# ioat91sam7x256 register map
Registers from a debugger description file.
Registers are 32-bit, access not given, no defined reset value unless marked. A register's access mark holds for its fields unless they carry their own. Addresses are absolute; registers are grouped by the start of their names; lines under a group give offsets from that group; [hi:lo] are bit positions; {n}, {i} and the like mark numbered series; 'fields as' and 'values as' point back to an identical list; <NAME> marks a mode.

## AIC
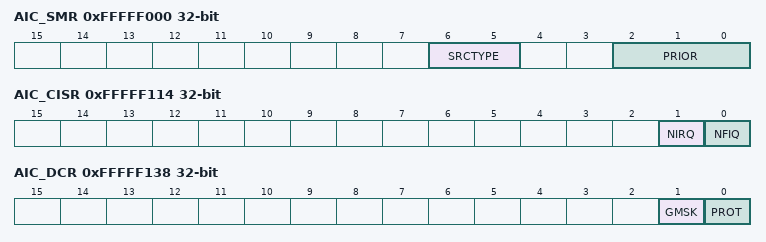
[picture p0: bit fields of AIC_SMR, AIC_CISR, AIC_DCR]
0xFFFFF000 AIC_SMR
  [6:5] SRCTYPE, [2:0] PRIOR
0xFFFFF080 AIC_SVR
0xFFFFF100 AIC_IVR
0xFFFFF104 AIC_FVR
0xFFFFF108 AIC_ISR
0xFFFFF10C AIC_IPR
0xFFFFF110 AIC_IMR
0xFFFFF114 AIC_CISR
  [1] NIRQ, [0] NFIQ
0xFFFFF120 AIC_IECR
0xFFFFF124 AIC_IDCR
0xFFFFF128 AIC_ICCR
0xFFFFF12C AIC_ISCR
0xFFFFF130 AIC_EOICR
0xFFFFF134 AIC_SPU
0xFFFFF138 AIC_DCR
  [1] GMSK, [0] PROT
0xFFFFF140 AIC_FFER
0xFFFFF144 AIC_FFDR
0xFFFFF148 AIC_FFSR

## DBGU
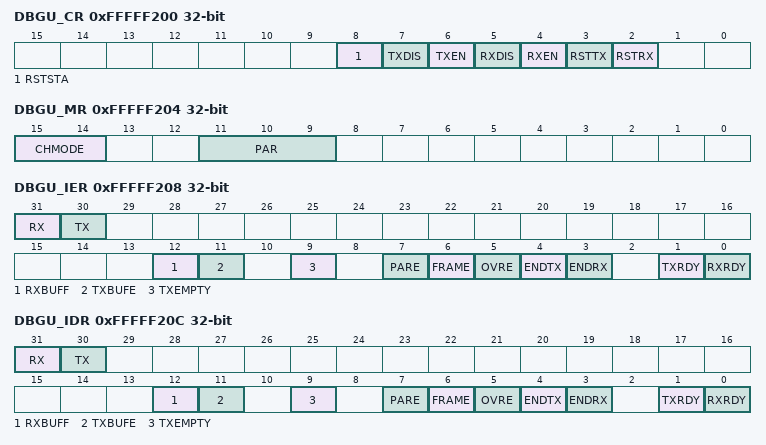
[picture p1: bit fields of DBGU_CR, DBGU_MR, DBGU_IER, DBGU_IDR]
0xFFFFF200 DBGU_CR
  [8] RSTSTA, [7] TXDIS, [6] TXEN, [5] RXDIS, [4] RXEN, [3] RSTTX, [2] RSTRX
0xFFFFF204 DBGU_MR
  [15:14] CHMODE, [11:9] PAR
0xFFFFF208 DBGU_IER
  [31] RX, [30] TX, [12] RXBUFF, [11] TXBUFE, [9] TXEMPTY, [7] PARE, [6] FRAME, [5] OVRE, [4] ENDTX, [3] ENDRX, [1] TXRDY, [0] RXRDY
0xFFFFF20C DBGU_IDR
  fields as DBGU_IER
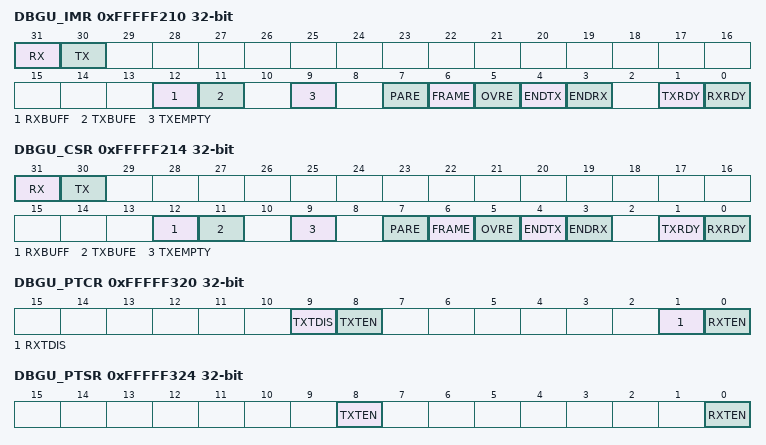
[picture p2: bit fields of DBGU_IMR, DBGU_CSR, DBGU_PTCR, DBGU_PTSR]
0xFFFFF210 DBGU_IMR
  fields as DBGU_IER
0xFFFFF214 DBGU_CSR
  fields as DBGU_IER
0xFFFFF218 DBGU_RHR
0xFFFFF21C DBGU_THR
0xFFFFF220 DBGU_BRGR
0xFFFFF240 DBGU_CIDR
0xFFFFF244 DBGU_EXID
0xFFFFF248 DBGU_FNTR
  [0] NTRST
0xFFFFF300 DBGU_RPR
0xFFFFF304 DBGU_RCR
0xFFFFF308 DBGU_TPR
0xFFFFF30C DBGU_TCR
0xFFFFF310 DBGU_RNPR
0xFFFFF314 DBGU_RNCR
0xFFFFF318 DBGU_TNPR
0xFFFFF31C DBGU_TNCR
0xFFFFF320 DBGU_PTCR
  [9] TXTDIS, [8] TXTEN, [1] RXTDIS, [0] RXTEN
0xFFFFF324 DBGU_PTSR
  [8] TXTEN, [0] RXTEN

## PIOA
0xFFFFF400 PIOA_PER
0xFFFFF404 PIOA_PDR
0xFFFFF408 PIOA_PSR
0xFFFFF410 PIOA_OER
0xFFFFF414 PIOA_ODR
0xFFFFF418 PIOA_OSR
0xFFFFF420 PIOA_IFER
0xFFFFF424 PIOA_IFDR
0xFFFFF428 PIOA_IFSR
0xFFFFF430 PIOA_SODR
0xFFFFF434 PIOA_CODR
0xFFFFF438 PIOA_ODSR
0xFFFFF43C PIOA_PDSR
0xFFFFF440 PIOA_IER
0xFFFFF444 PIOA_IDR
0xFFFFF448 PIOA_IMR
0xFFFFF44C PIOA_ISR
0xFFFFF450 PIOA_MDER
0xFFFFF454 PIOA_MDDR
0xFFFFF458 PIOA_MDSR
0xFFFFF460 PIOA_PPUDR
0xFFFFF464 PIOA_PPUER
0xFFFFF468 PIOA_PPUSR
0xFFFFF470 PIOA_ASR
0xFFFFF474 PIOA_BSR
0xFFFFF478 PIOA_ABSR
0xFFFFF4A0 PIOA_OWER
0xFFFFF4A4 PIOA_OWDR
0xFFFFF4A8 PIOA_OWSR

## PIOB
0xFFFFF600 PIOB_PER
0xFFFFF604 PIOB_PDR
0xFFFFF608 PIOB_PSR
0xFFFFF610 PIOB_OER
0xFFFFF614 PIOB_ODR
0xFFFFF618 PIOB_OSR
0xFFFFF620 PIOB_IFER
0xFFFFF624 PIOB_IFDR
0xFFFFF628 PIOB_IFSR
0xFFFFF630 PIOB_SODR
0xFFFFF634 PIOB_CODR
0xFFFFF638 PIOB_ODSR
0xFFFFF63C PIOB_PDSR
0xFFFFF640 PIOB_IER
0xFFFFF644 PIOB_IDR
0xFFFFF648 PIOB_IMR
0xFFFFF64C PIOB_ISR
0xFFFFF650 PIOB_MDER
0xFFFFF654 PIOB_MDDR
0xFFFFF658 PIOB_MDSR
0xFFFFF660 PIOB_PPUDR
0xFFFFF664 PIOB_PPUER
0xFFFFF668 PIOB_PPUSR
0xFFFFF670 PIOB_ASR
0xFFFFF674 PIOB_BSR
0xFFFFF678 PIOB_ABSR
0xFFFFF6A0 PIOB_OWER
0xFFFFF6A4 PIOB_OWDR
0xFFFFF6A8 PIOB_OWSR

## CKGR
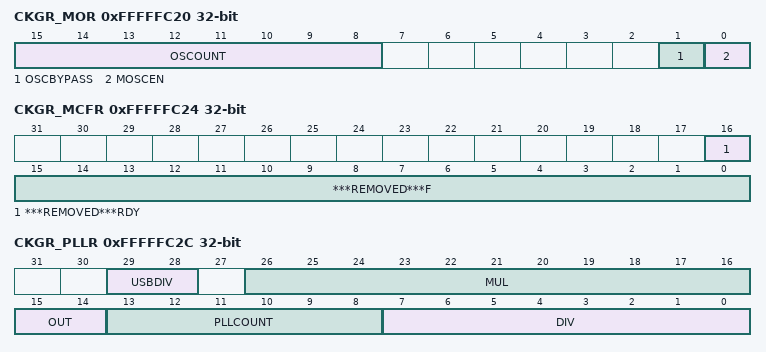
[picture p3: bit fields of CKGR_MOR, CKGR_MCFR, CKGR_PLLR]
0xFFFFFC20 CKGR_MOR
  [15:8] OSCOUNT, [1] OSCBYPASS, [0] MOSCEN
0xFFFFFC24 CKGR_MCFR
  [16] ***REMOVED***RDY, [15:0] ***REMOVED***F
0xFFFFFC2C CKGR_PLLR
  [29:28] USBDIV, [26:16] MUL, [15:14] OUT, [13:8] PLLCOUNT, [7:0] DIV

## PMC
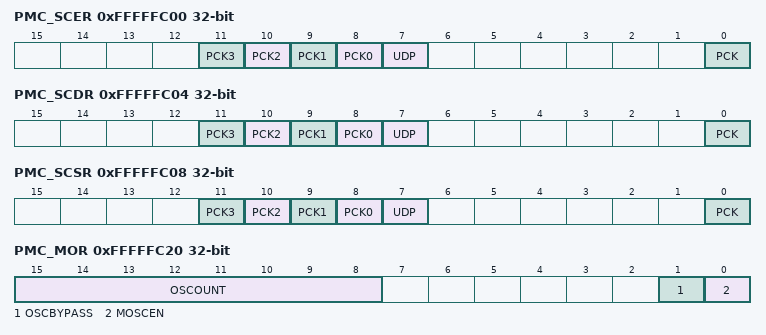
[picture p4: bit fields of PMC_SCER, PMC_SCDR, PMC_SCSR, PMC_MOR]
0xFFFFFC00 PMC_SCER
  [n+8] PCK{n} (n=0..3), [7] UDP, [0] PCK
0xFFFFFC04 PMC_SCDR
  [n+8] PCK{n} (n=0..3), [7] UDP, [0] PCK
0xFFFFFC08 PMC_SCSR
  [n+8] PCK{n} (n=0..3), [7] UDP, [0] PCK
0xFFFFFC10 PMC_PCER
0xFFFFFC14 PMC_PCDR
0xFFFFFC18 PMC_PCSR
0xFFFFFC20 PMC_MOR
  [15:8] OSCOUNT, [1] OSCBYPASS, [0] MOSCEN
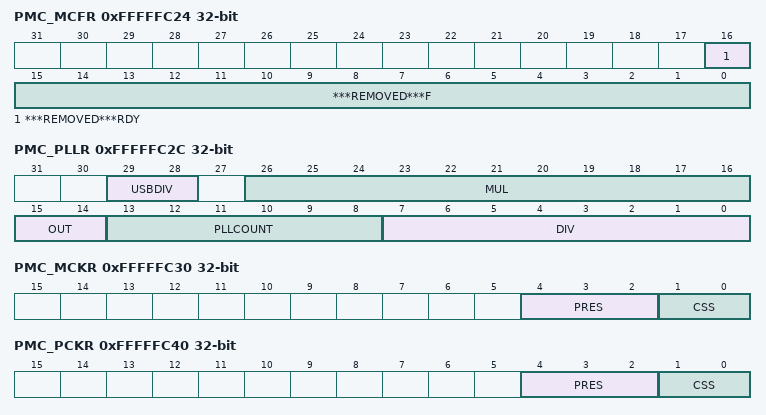
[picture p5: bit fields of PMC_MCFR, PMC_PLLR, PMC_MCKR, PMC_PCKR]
0xFFFFFC24 PMC_MCFR
  [16] ***REMOVED***RDY, [15:0] ***REMOVED***F
0xFFFFFC2C PMC_PLLR
  [29:28] USBDIV, [26:16] MUL, [15:14] OUT, [13:8] PLLCOUNT, [7:0] DIV
0xFFFFFC30 PMC_MCKR
  [4:2] PRES, [1:0] CSS
0xFFFFFC40 PMC_PCKR
  [4:2] PRES, [1:0] CSS
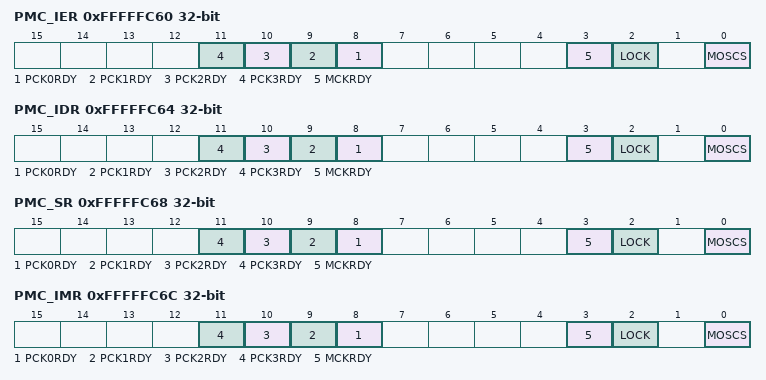
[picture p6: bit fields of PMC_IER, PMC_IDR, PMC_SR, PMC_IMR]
0xFFFFFC60 PMC_IER
  [n+8] PCK{n}RDY (n=0..3), [3] MCKRDY, [2] LOCK, [0] MOSCS
0xFFFFFC64 PMC_IDR
  [n+8] PCK{n}RDY (n=0..3), [3] MCKRDY, [2] LOCK, [0] MOSCS
0xFFFFFC68 PMC_SR
  [n+8] PCK{n}RDY (n=0..3), [3] MCKRDY, [2] LOCK, [0] MOSCS
0xFFFFFC6C PMC_IMR
  [n+8] PCK{n}RDY (n=0..3), [3] MCKRDY, [2] LOCK, [0] MOSCS
